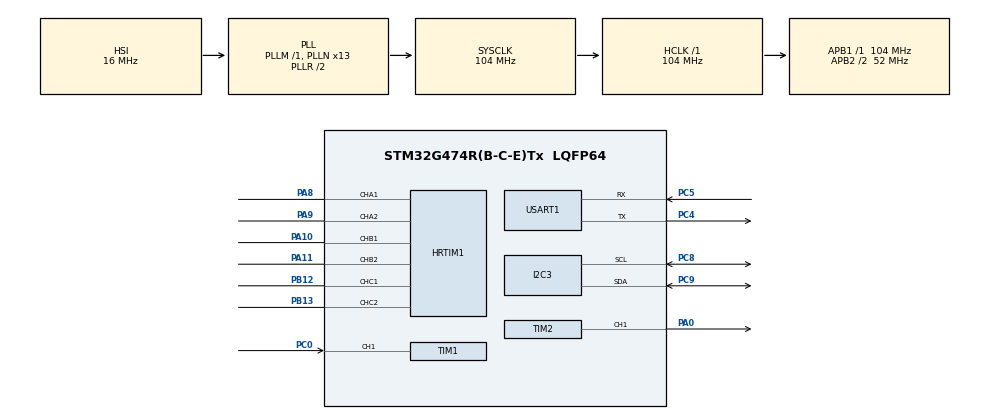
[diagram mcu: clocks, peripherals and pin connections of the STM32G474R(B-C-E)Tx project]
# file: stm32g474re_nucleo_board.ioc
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Dma.Request0=USART1_RX
Dma.Request1=USART1_TX
Dma.USART1_RX.0.Direction=DMA_PERIPH_TO_MEMORY
Dma.USART1_RX.0.EventEnable=DISABLE
Dma.USART1_RX.0.Instance=DMA1_Channel1
Dma.USART1_RX.0.MemDataAlignment=DMA_MDATAALIGN_BYTE
Dma.USART1_RX.0.MemInc=DMA_MINC_ENABLE
Dma.USART1_RX.0.Mode=DMA_NORMAL
Dma.USART1_RX.0.PeriphDataAlignment=DMA_PDATAALIGN_BYTE
Dma.USART1_RX.0.PeriphInc=DMA_PINC_DISABLE
Dma.USART1_RX.0.Polarity=HAL_DMAMUX_REQ_GEN_RISING
Dma.USART1_RX.0.Priority=DMA_PRIORITY_LOW
Dma.USART1_RX.0.RequestNumber=1
Dma.USART1_RX.0.SignalID=NONE
Dma.USART1_RX.0.SyncEnable=DISABLE
Dma.USART1_RX.0.SyncPolarity=HAL_DMAMUX_SYNC_NO_EVENT
Dma.USART1_RX.0.SyncRequestNumber=1
Dma.USART1_RX.0.SyncSignalID=NONE
Dma.USART1_TX.1.Direction=DMA_MEMORY_TO_PERIPH
Dma.USART1_TX.1.EventEnable=DISABLE
Dma.USART1_TX.1.Instance=DMA1_Channel2
Dma.USART1_TX.1.MemDataAlignment=DMA_MDATAALIGN_BYTE
Dma.USART1_TX.1.MemInc=DMA_MINC_ENABLE
Dma.USART1_TX.1.Mode=DMA_NORMAL
Dma.USART1_TX.1.PeriphDataAlignment=DMA_PDATAALIGN_BYTE
Dma.USART1_TX.1.PeriphInc=DMA_PINC_DISABLE
Dma.USART1_TX.1.Polarity=HAL_DMAMUX_REQ_GEN_RISING
Dma.USART1_TX.1.Priority=DMA_PRIORITY_MEDIUM
Dma.USART1_TX.1.RequestNumber=1
Dma.USART1_TX.1.SignalID=NONE
Dma.USART1_TX.1.SyncEnable=DISABLE
Dma.USART1_TX.1.SyncPolarity=HAL_DMAMUX_SYNC_NO_EVENT
Dma.USART1_TX.1.SyncRequestNumber=1
Dma.USART1_TX.1.SyncSignalID=NONE
FREERTOS.HEAP_NUMBER=3
FREERTOS.Tasks01=defaultTask,24,128,StartDefaultTask,Default,NULL,Dynamic,NULL,NULL
FREERTOS.configLIBRARY_MAX_SYSCALL_INTERRUPT_PRIORITY=5
FREERTOS.configTOTAL_HEAP_SIZE=0x6000
FREERTOS.configUSE_NEWLIB_REENTRANT=1
HRTIM1.CompareUnit1-Output_TA1TA2=HRTIM_COMPAREUNIT_1
HRTIM1.CompareValue1-Output_TA1TA2=0
HRTIM1.DeadTimeInsertion-Output_TB1TB2=HRTIM_TIMDEADTIMEINSERTION_ENABLED
HRTIM1.DeadTimeInsertion-Output_TC1TC2=HRTIM_TIMDEADTIMEINSERTION_ENABLED
HRTIM1.Deadtimeconfig-Output_TA1TA2=HRTIM_TIMERINDEX_TIMER_A
HRTIM1.ModeTimeBase-Output_TA1TA2=HRTIM_MODE_SINGLESHOT_RETRIGGERABLE
HRTIM1.ModeTimeBase-Output_TB1TB2=HRTIM_MODE_SINGLESHOT_RETRIGGERABLE
HRTIM1.ModeTimeBase-Output_TC1TC2=HRTIM_MODE_SINGLESHOT_RETRIGGERABLE
HRTIM1.NumberResetSource1-Output_TA1TA2=1
HRTIM1.NumberResetSource2_TA=1
HRTIM1.NumberSetSource1-Output_TA1TA2=1
HRTIM1.NumberSetSource2_TA=1
HRTIM1.ResetOnSync-Output_TA1TA2=HRTIM_SYNCRESET_ENABLED
HRTIM1.ResetOnSync-Output_TB1TB2=HRTIM_SYNCRESET_ENABLED
HRTIM1.ResetOnSync-Output_TC1TC2=HRTIM_SYNCRESET_ENABLED
HRTIM1.ResetOutput1_Source1-Output_TA1TA2=HRTIM_OUTPUTRESET_TIMCMP1
HRTIM1.ResetOutput2_Source1-Output_TA1TA2=HRTIM_OUTPUTRESET_TIMCMP1
HRTIM1.SetOutput1_Source1-Output_TA1TA2=HRTIM_OUTPUTSET_TIMCMP1
HRTIM1.SetOutput2_Source1-Output_TA1TA2=HRTIM_OUTPUTSET_TIMCMP1
HRTIM1.StartOnSync-Output_TA1TA2=HRTIM_SYNCSTART_ENABLED
HRTIM1.StartOnSync-Output_TB1TB2=HRTIM_SYNCSTART_ENABLED
HRTIM1.StartOnSync-Output_TC1TC2=HRTIM_SYNCSTART_ENABLED
HRTIM1.SyncInputSource=HRTIM_SYNCINPUTSOURCE_INTERNALEVENT
HRTIM1.SyncOptions=HRTIM_SYNCOPTION_SLAVE
I2C3.Timing=0x20C18EBF
Mcu.Family=STM32G4
Mcu.Name=STM32G474R(B-C-E)Tx
Mcu.Package=LQFP64
NVIC.DMA1_Channel1_IRQn=true\:5\:0\:false\:false\:true\:true\:false\:true\:true
NVIC.DMA1_Channel2_IRQn=true\:5\:0\:false\:false\:true\:false\:false\:true\:true
NVIC.PriorityGroup=NVIC_PRIORITYGROUP_4
NVIC.TIM1_CC_IRQn=true\:5\:0\:false\:false\:true\:true\:true\:true\:true
NVIC.TIM20_UP_IRQn=true\:15\:0\:false\:false\:true\:false\:false\:true\:true
NVIC.TimeBase=TIM20_UP_IRQn
NVIC.TimeBaseIP=TIM20
NVIC.USART1_IRQn=true\:5\:0\:true\:false\:true\:true\:true\:true\:true
PA0.Signal=S_TIM2_CH1
PA10.Mode=Output_TB1TB2
PA10.Signal=HRTIM1_CHB1
PA11.Mode=Output_TB1TB2
PA11.Signal=HRTIM1_CHB2
PA13.Mode=Trace_Asynchronous_SW
PA13.Signal=SYS_JTMS-SWDIO
PA14.Mode=Trace_Asynchronous_SW
PA14.Signal=SYS_JTCK-SWCLK
PA8.Mode=Output_TA1TA2
PA8.Signal=HRTIM1_CHA1
PA9.Mode=Output_TA1TA2
PA9.Signal=HRTIM1_CHA2
PB12.Mode=Output_TC1TC2
PB12.Signal=HRTIM1_CHC1
PB13.Mode=Output_TC1TC2
PB13.Signal=HRTIM1_CHC2
PB3.Mode=Trace_Asynchronous_SW
PB3.Signal=SYS_JTDO-SWO
PC0.Signal=S_TIM1_CH1
PC4.Mode=Asynchronous
PC4.Signal=USART1_TX
PC5.GPIO_PuPd=GPIO_PULLUP
PC5.Mode=Asynchronous
PC5.Signal=USART1_RX
PC8.GPIO_Pu=GPIO_PULLUP
PC8.Mode=I2C
PC8.Signal=I2C3_SCL
PC9.GPIO_Pu=GPIO_PULLUP
PC9.Mode=I2C
PC9.Signal=I2C3_SDA
ProjectManager.HeapSize=0x200
ProjectManager.StackSize=0x400
ProjectManager.TargetToolchain=CMake
RCC.ADC12Freq_Value=104000000
RCC.ADC345Freq_Value=104000000
RCC.AHBFreq_Value=104000000
RCC.APB1Freq_Value=104000000
RCC.APB1TimFreq_Value=104000000
RCC.APB2CLKDivider=RCC_HCLK_DIV2
RCC.APB2Freq_Value=52000000
RCC.APB2TimFreq_Value=104000000
RCC.CortexFreq_Value=104000000
RCC.EXTERNAL_CLOCK_VALUE=12288000
RCC.HCLKFreq_Value=104000000
RCC.HSE_VALUE=8000000
RCC.HSI48_VALUE=48000000
RCC.HSI_VALUE=16000000
RCC.LSE_VALUE=32768
RCC.PLLN=13
RCC.SYSCLKFreq_VALUE=104000000
RCC.SYSCLKSource=RCC_SYSCLKSOURCE_PLLCLK
RCC.USBFreq_Value=104000000
RCC.VCOOutputFreq_Value=208000000
SH.S_TIM1_CH1.0=TIM1_CH1,TriggerSource_TI1ED
SH.S_TIM2_CH1.0=TIM2_CH1,PWM Generation1 CH1
TIM1.Channel-Input_Capture1_from_TRC=TIM_CHANNEL_1
TIM1.TIM_MasterOutputTrigger=TIM_TRGO_OC1
TIM1.TIM_MasterSlaveMode=TIM_MASTERSLAVEMODE_ENABLE
TIM2.Channel-PWM\ Generation1\ CH1=TIM_CHANNEL_1
TIM2.PeriodNoDither=32768
TIM2.PulseNoDither_1=16384
USART1.FIFOMode=FIFOMODE_DISABLE
USART1.VirtualMode-Asynchronous=VM_ASYNC
VP_CRC_VS_CRC.Mode=CRC_Activate
VP_FREERTOS_VS_CMSIS_V2.Mode=CMSIS_V2
VP_HRTIM1_VS_hrtimMasterTimerNoOutput.Mode=MasterTimer
VP_HRTIM1_VirtualSync.Mode=SCOUT_SCINmodeVirtual
VP_SYS_VS_DBSignals.Mode=DisableDeadBatterySignals
VP_SYS_VS_tim20.Mode=TIM20
VP_TIM1_VS_CH1.Mode=Input_Capture1_from_TRC
VP_TIM1_VS_ClockSourceINT.Mode=Internal
VP_TIM1_VS_ControllerModeCombinedResetTrigger.Mode=Combined_Reset_Trigger_Mode
VP_TIM2_VS_ClockSourceINT.Mode=Internal
board=custom

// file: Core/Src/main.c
/* USER CODE BEGIN Header */
/**
  ******************************************************************************
  * @file           : main.c
  * @brief          : Main program body
  ******************************************************************************
  * @attention
  *
  * Copyright (c) 2025 STMicroelectronics.
  * All rights reserved.
  *
  * This software is licensed under terms that can be found in the LICENSE file
  * in the root directory of this software component.
  * If no LICENSE file comes with this software, it is provided AS-IS.
  *
  ******************************************************************************
  */
/* USER CODE END Header */
#include "main.h"
#include "cmsis_os.h"

/* USER CODE BEGIN PTD */

/* Use g_board_* naming from board.h */
#include "board.h"

/* USER CODE END PTD */

CRC_HandleTypeDef hcrc;

HRTIM_HandleTypeDef hhrtim1;

I2C_HandleTypeDef hi2c3;

TIM_HandleTypeDef htim1;
TIM_HandleTypeDef htim2;

UART_HandleTypeDef huart1;
DMA_HandleTypeDef hdma_usart1_rx;
DMA_HandleTypeDef hdma_usart1_tx;

/* Board config - g_board_* naming for controller code */
TIM_HandleTypeDef *g_board_tim_feedback = &htim1;
TIM_HandleTypeDef *g_board_tim_debug = &htim2;
HRTIM_HandleTypeDef *g_board_hrtim = &hhrtim1;
I2C_HandleTypeDef *g_board_i2c_internal = &hi2c3;
UART_HandleTypeDef *g_board_ctl_uart = &huart1;
DMA_HandleTypeDef *g_board_dma_uart_rx = &hdma_usart1_rx;
DMA_HandleTypeDef *g_board_dma_uart_tx = &hdma_usart1_tx;
CRC_HandleTypeDef *g_board_crc32 = &hcrc;

// BOARD_CONFIG instance - references to board peripherals
struct BoardConfig g_board_config = {
    .message_bus = &huart1,
    .crc32 = &hcrc
};

DAC_HandleTypeDef *g_board_dac_ch1 = (DAC_HandleTypeDef *)0;
DAC_HandleTypeDef *g_board_dac_ch2 = (DAC_HandleTypeDef *)0;
DAC_HandleTypeDef *g_board_dac_ch3 = (DAC_HandleTypeDef *)0;
DAC_HandleTypeDef *g_board_dac_ch4 = (DAC_HandleTypeDef *)0;
DAC_HandleTypeDef *g_board_dac_channels[4] = {
    (DAC_HandleTypeDef *)0,
    (DAC_HandleTypeDef *)0,
    (DAC_HandleTypeDef *)0,
    (DAC_HandleTypeDef *)0
};

/* Definitions for defaultTask */
osThreadId_t defaultTaskHandle;
const osThreadAttr_t defaultTask_attributes = {
  .name = "defaultTask",
  .priority = (osPriority_t) osPriorityNormal,
  .stack_size = 128 * 4
};
/* USER CODE BEGIN PV */
// Board definition macro (selected by CMake -DBOARD=...)
#define stm32g474re_nucleo_board
/* USER CODE END PV */

void SystemClock_Config(void);
static void MX_GPIO_Init(void);
static void MX_DMA_Init(void);
static void MX_HRTIM1_Init(void);
static void MX_TIM1_Init(void);
static void MX_TIM2_Init(void);
static void MX_I2C3_Init(void);
static void MX_CRC_Init(void);
static void MX_USART1_UART_Init(void);
void StartDefaultTask(void *argument);

int main(void)
{

  /* MCU Configuration--------------------------------------------------------*/

  /* Reset of all peripherals, Initializes the Flash interface and the Systick. */
  HAL_Init();

  /* Configure the system clock */
  SystemClock_Config();

  /* Initialize all configured peripherals */
  MX_GPIO_Init();
  MX_DMA_Init();
  MX_HRTIM1_Init();
  MX_TIM1_Init();
  MX_TIM2_Init();
  MX_I2C3_Init();
  MX_CRC_Init();
  MX_USART1_UART_Init();

  /* Init scheduler */
  osKernelInitialize();

  /* Create the thread(s) */
  /* creation of defaultTask */
  defaultTaskHandle = osThreadNew(StartDefaultTask, NULL, &defaultTask_attributes);

  /* Start scheduler */
  osKernelStart();

  /* We should never get here as control is now taken by the scheduler */

  /* Infinite loop */
  while (1)
  {

  }
}

void SystemClock_Config(void)
{
  RCC_OscInitTypeDef RCC_OscInitStruct = {0};
  RCC_ClkInitTypeDef RCC_ClkInitStruct = {0};

  /** Configure the main internal regulator output voltage
  */
  HAL_PWREx_ControlVoltageScaling(PWR_REGULATOR_VOLTAGE_SCALE1);

  /** Initializes the RCC Oscillators according to the specified parameters
  * in the RCC_OscInitTypeDef structure.
  */
  RCC_OscInitStruct.OscillatorType = RCC_OSCILLATORTYPE_HSI;
  RCC_OscInitStruct.HSIState = RCC_HSI_ON;
  RCC_OscInitStruct.HSICalibrationValue = RCC_HSICALIBRATION_DEFAULT;
  RCC_OscInitStruct.PLL.PLLState = RCC_PLL_ON;
  RCC_OscInitStruct.PLL.PLLSource = RCC_PLLSOURCE_HSI;
  RCC_OscInitStruct.PLL.PLLM = RCC_PLLM_DIV1;
  RCC_OscInitStruct.PLL.PLLN = 13;
  RCC_OscInitStruct.PLL.PLLP = RCC_PLLP_DIV2;
  RCC_OscInitStruct.PLL.PLLQ = RCC_PLLQ_DIV2;
  RCC_OscInitStruct.PLL.PLLR = RCC_PLLR_DIV2;
  if (HAL_RCC_OscConfig(&RCC_OscInitStruct) != HAL_OK)
  {
    Error_Handler();
  }

  /** Initializes the CPU, AHB and APB buses clocks
  */
  RCC_ClkInitStruct.ClockType = RCC_CLOCKTYPE_HCLK|RCC_CLOCKTYPE_SYSCLK
                              |RCC_CLOCKTYPE_PCLK1|RCC_CLOCKTYPE_PCLK2;
  RCC_ClkInitStruct.SYSCLKSource = RCC_SYSCLKSOURCE_PLLCLK;
  RCC_ClkInitStruct.AHBCLKDivider = RCC_SYSCLK_DIV1;
  RCC_ClkInitStruct.APB1CLKDivider = RCC_HCLK_DIV1;
  RCC_ClkInitStruct.APB2CLKDivider = RCC_HCLK_DIV2;

  if (HAL_RCC_ClockConfig(&RCC_ClkInitStruct, FLASH_LATENCY_3) != HAL_OK)
  {
    Error_Handler();
  }
}

static void MX_CRC_Init(void)
{

  hcrc.Instance = CRC;
  hcrc.Init.DefaultPolynomialUse = DEFAULT_POLYNOMIAL_ENABLE;
  hcrc.Init.DefaultInitValueUse = DEFAULT_INIT_VALUE_ENABLE;
  hcrc.Init.InputDataInversionMode = CRC_INPUTDATA_INVERSION_NONE;
  hcrc.Init.OutputDataInversionMode = CRC_OUTPUTDATA_INVERSION_DISABLE;
  hcrc.InputDataFormat = CRC_INPUTDATA_FORMAT_BYTES;
  if (HAL_CRC_Init(&hcrc) != HAL_OK)
  {
    Error_Handler();
  }

}

static void MX_HRTIM1_Init(void)
{

  HRTIM_TimeBaseCfgTypeDef pTimeBaseCfg = {0};
  HRTIM_TimerCfgTypeDef pTimerCfg = {0};
  HRTIM_TimerCtlTypeDef pTimerCtl = {0};
  HRTIM_CompareCfgTypeDef pCompareCfg = {0};
  HRTIM_DeadTimeCfgTypeDef pDeadTimeCfg = {0};
  HRTIM_OutputCfgTypeDef pOutputCfg = {0};

  hhrtim1.Instance = HRTIM1;
  hhrtim1.Init.HRTIMInterruptResquests = HRTIM_IT_NONE;
  hhrtim1.Init.SyncOptions = HRTIM_SYNCOPTION_SLAVE;
  hhrtim1.Init.SyncInputSource = HRTIM_SYNCINPUTSOURCE_INTERNALEVENT;
  if (HAL_HRTIM_Init(&hhrtim1) != HAL_OK)
  {
    Error_Handler();
  }
  if (HAL_HRTIM_DLLCalibrationStart(&hhrtim1, HRTIM_CALIBRATIONRATE_3) != HAL_OK)
  {
    Error_Handler();
  }
  if (HAL_HRTIM_PollForDLLCalibration(&hhrtim1, 10) != HAL_OK)
  {
    Error_Handler();
  }
  pTimeBaseCfg.Period = 0xFFDF;
  pTimeBaseCfg.RepetitionCounter = 0x00;
  pTimeBaseCfg.PrescalerRatio = HRTIM_PRESCALERRATIO_MUL32;
  pTimeBaseCfg.Mode = HRTIM_MODE_CONTINUOUS;
  if (HAL_HRTIM_TimeBaseConfig(&hhrtim1, HRTIM_TIMERINDEX_MASTER, &pTimeBaseCfg) != HAL_OK)
  {
    Error_Handler();
  }
  pTimerCfg.InterruptRequests = HRTIM_MASTER_IT_NONE;
  pTimerCfg.DMARequests = HRTIM_MASTER_DMA_NONE;
  pTimerCfg.DMASrcAddress = 0x0000;
  pTimerCfg.DMADstAddress = 0x0000;
  pTimerCfg.DMASize = 0x1;
  pTimerCfg.HalfModeEnable = HRTIM_HALFMODE_DISABLED;
  pTimerCfg.InterleavedMode = HRTIM_INTERLEAVED_MODE_DISABLED;
  pTimerCfg.StartOnSync = HRTIM_SYNCSTART_DISABLED;
  pTimerCfg.ResetOnSync = HRTIM_SYNCRESET_DISABLED;
  pTimerCfg.DACSynchro = HRTIM_DACSYNC_NONE;
  pTimerCfg.PreloadEnable = HRTIM_PRELOAD_DISABLED;
  pTimerCfg.UpdateGating = HRTIM_UPDATEGATING_INDEPENDENT;
  pTimerCfg.BurstMode = HRTIM_TIMERBURSTMODE_MAINTAINCLOCK;
  pTimerCfg.RepetitionUpdate = HRTIM_UPDATEONREPETITION_DISABLED;
  pTimerCfg.ReSyncUpdate = HRTIM_TIMERESYNC_UPDATE_UNCONDITIONAL;
  if (HAL_HRTIM_WaveformTimerConfig(&hhrtim1, HRTIM_TIMERINDEX_MASTER, &pTimerCfg) != HAL_OK)
  {
    Error_Handler();
  }
  pTimeBaseCfg.Mode = HRTIM_MODE_SINGLESHOT_RETRIGGERABLE;
  if (HAL_HRTIM_TimeBaseConfig(&hhrtim1, HRTIM_TIMERINDEX_TIMER_A, &pTimeBaseCfg) != HAL_OK)
  {
    Error_Handler();
  }
  pTimerCtl.UpDownMode = HRTIM_TIMERUPDOWNMODE_UP;
  pTimerCtl.GreaterCMP1 = HRTIM_TIMERGTCMP1_EQUAL;
  pTimerCtl.DualChannelDacEnable = HRTIM_TIMER_DCDE_DISABLED;
  if (HAL_HRTIM_WaveformTimerControl(&hhrtim1, HRTIM_TIMERINDEX_TIMER_A, &pTimerCtl) != HAL_OK)
  {
    Error_Handler();
  }
  pTimerCfg.InterruptRequests = HRTIM_TIM_IT_NONE;
  pTimerCfg.DMARequests = HRTIM_TIM_DMA_NONE;
  pTimerCfg.StartOnSync = HRTIM_SYNCSTART_ENABLED;
  pTimerCfg.ResetOnSync = HRTIM_SYNCRESET_ENABLED;
  pTimerCfg.PushPull = HRTIM_TIMPUSHPULLMODE_DISABLED;
  pTimerCfg.FaultEnable = HRTIM_TIMFAULTENABLE_NONE;
  pTimerCfg.FaultLock = HRTIM_TIMFAULTLOCK_READWRITE;
  pTimerCfg.DeadTimeInsertion = HRTIM_TIMDEADTIMEINSERTION_DISABLED;
  pTimerCfg.DelayedProtectionMode = HRTIM_TIMER_A_B_C_DELAYEDPROTECTION_DISABLED;
  pTimerCfg.UpdateTrigger = HRTIM_TIMUPDATETRIGGER_NONE;
  pTimerCfg.ResetTrigger = HRTIM_TIMRESETTRIGGER_NONE;
  pTimerCfg.ResetUpdate = HRTIM_TIMUPDATEONRESET_DISABLED;
  if (HAL_HRTIM_WaveformTimerConfig(&hhrtim1, HRTIM_TIMERINDEX_TIMER_A, &pTimerCfg) != HAL_OK)
  {
    Error_Handler();
  }
  pTimerCfg.DeadTimeInsertion = HRTIM_TIMDEADTIMEINSERTION_ENABLED;
  if (HAL_HRTIM_WaveformTimerConfig(&hhrtim1, HRTIM_TIMERINDEX_TIMER_B, &pTimerCfg) != HAL_OK)
  {
    Error_Handler();
  }
  if (HAL_HRTIM_WaveformTimerConfig(&hhrtim1, HRTIM_TIMERINDEX_TIMER_C, &pTimerCfg) != HAL_OK)
  {
    Error_Handler();
  }
  pCompareCfg.CompareValue = 0;
  if (HAL_HRTIM_WaveformCompareConfig(&hhrtim1, HRTIM_TIMERINDEX_TIMER_A, HRTIM_COMPAREUNIT_1, &pCompareCfg) != HAL_OK)
  {
    Error_Handler();
  }
  pDeadTimeCfg.Prescaler = HRTIM_TIMDEADTIME_PRESCALERRATIO_MUL8;
  pDeadTimeCfg.RisingValue = 0x000;
  pDeadTimeCfg.RisingSign = HRTIM_TIMDEADTIME_RISINGSIGN_POSITIVE;
  pDeadTimeCfg.RisingLock = HRTIM_TIMDEADTIME_RISINGLOCK_WRITE;
  pDeadTimeCfg.RisingSignLock = HRTIM_TIMDEADTIME_RISINGSIGNLOCK_WRITE;
  pDeadTimeCfg.FallingValue = 0x000;
  pDeadTimeCfg.FallingSign = HRTIM_TIMDEADTIME_FALLINGSIGN_POSITIVE;
  pDeadTimeCfg.FallingLock = HRTIM_TIMDEADTIME_FALLINGLOCK_WRITE;
  pDeadTimeCfg.FallingSignLock = HRTIM_TIMDEADTIME_FALLINGSIGNLOCK_WRITE;
  if (HAL_HRTIM_DeadTimeConfig(&hhrtim1, HRTIM_TIMERINDEX_TIMER_A, &pDeadTimeCfg) != HAL_OK)
  {
    Error_Handler();
  }
  if (HAL_HRTIM_DeadTimeConfig(&hhrtim1, HRTIM_TIMERINDEX_TIMER_B, &pDeadTimeCfg) != HAL_OK)
  {
    Error_Handler();
  }
  if (HAL_HRTIM_DeadTimeConfig(&hhrtim1, HRTIM_TIMERINDEX_TIMER_C, &pDeadTimeCfg) != HAL_OK)
  {
    Error_Handler();
  }
  pOutputCfg.Polarity = HRTIM_OUTPUTPOLARITY_HIGH;
  pOutputCfg.SetSource = HRTIM_OUTPUTSET_TIMCMP1;
  pOutputCfg.ResetSource = HRTIM_OUTPUTRESET_TIMCMP1;
  pOutputCfg.IdleMode = HRTIM_OUTPUTIDLEMODE_NONE;
  pOutputCfg.IdleLevel = HRTIM_OUTPUTIDLELEVEL_INACTIVE;
  pOutputCfg.FaultLevel = HRTIM_OUTPUTFAULTLEVEL_NONE;
  pOutputCfg.ChopperModeEnable = HRTIM_OUTPUTCHOPPERMODE_DISABLED;
  pOutputCfg.BurstModeEntryDelayed = HRTIM_OUTPUTBURSTMODEENTRY_REGULAR;
  if (HAL_HRTIM_WaveformOutputConfig(&hhrtim1, HRTIM_TIMERINDEX_TIMER_A, HRTIM_OUTPUT_TA1, &pOutputCfg) != HAL_OK)
  {
    Error_Handler();
  }
  pOutputCfg.SetSource = HRTIM_OUTPUTSET_NONE;
  pOutputCfg.ResetSource = HRTIM_OUTPUTRESET_NONE;
  if (HAL_HRTIM_WaveformOutputConfig(&hhrtim1, HRTIM_TIMERINDEX_TIMER_B, HRTIM_OUTPUT_TB1, &pOutputCfg) != HAL_OK)
  {
    Error_Handler();
  }
  if (HAL_HRTIM_WaveformOutputConfig(&hhrtim1, HRTIM_TIMERINDEX_TIMER_C, HRTIM_OUTPUT_TC1, &pOutputCfg) != HAL_OK)
  {
    Error_Handler();
  }
  pOutputCfg.SetSource = HRTIM_OUTPUTSET_TIMCMP1;
  pOutputCfg.ResetSource = HRTIM_OUTPUTRESET_TIMCMP1;
  if (HAL_HRTIM_WaveformOutputConfig(&hhrtim1, HRTIM_TIMERINDEX_TIMER_A, HRTIM_OUTPUT_TA2, &pOutputCfg) != HAL_OK)
  {
    Error_Handler();
  }
  pOutputCfg.SetSource = HRTIM_OUTPUTSET_NONE;
  pOutputCfg.ResetSource = HRTIM_OUTPUTRESET_NONE;
  if (HAL_HRTIM_WaveformOutputConfig(&hhrtim1, HRTIM_TIMERINDEX_TIMER_B, HRTIM_OUTPUT_TB2, &pOutputCfg) != HAL_OK)
  {
    Error_Handler();
  }
  if (HAL_HRTIM_WaveformOutputConfig(&hhrtim1, HRTIM_TIMERINDEX_TIMER_C, HRTIM_OUTPUT_TC2, &pOutputCfg) != HAL_OK)
  {
    Error_Handler();
  }
  if (HAL_HRTIM_TimeBaseConfig(&hhrtim1, HRTIM_TIMERINDEX_TIMER_B, &pTimeBaseCfg) != HAL_OK)
  {
    Error_Handler();
  }
  if (HAL_HRTIM_WaveformTimerControl(&hhrtim1, HRTIM_TIMERINDEX_TIMER_B, &pTimerCtl) != HAL_OK)
  {
    Error_Handler();
  }
  if (HAL_HRTIM_TimeBaseConfig(&hhrtim1, HRTIM_TIMERINDEX_TIMER_C, &pTimeBaseCfg) != HAL_OK)
  {
    Error_Handler();
  }
  if (HAL_HRTIM_WaveformTimerControl(&hhrtim1, HRTIM_TIMERINDEX_TIMER_C, &pTimerCtl) != HAL_OK)
  {
    Error_Handler();
  }
  HAL_HRTIM_MspPostInit(&hhrtim1);

}

static void MX_I2C3_Init(void)
{

  hi2c3.Instance = I2C3;
  hi2c3.Init.Timing = 0x20C18EBF;
  hi2c3.Init.OwnAddress1 = 0;
  hi2c3.Init.AddressingMode = I2C_ADDRESSINGMODE_7BIT;
  hi2c3.Init.DualAddressMode = I2C_DUALADDRESS_DISABLE;
  hi2c3.Init.OwnAddress2 = 0;
  hi2c3.Init.OwnAddress2Masks = I2C_OA2_NOMASK;
  hi2c3.Init.GeneralCallMode = I2C_GENERALCALL_DISABLE;
  hi2c3.Init.NoStretchMode = I2C_NOSTRETCH_DISABLE;
  if (HAL_I2C_Init(&hi2c3) != HAL_OK)
  {
    Error_Handler();
  }

  /** Configure Analogue filter
  */
  if (HAL_I2CEx_ConfigAnalogFilter(&hi2c3, I2C_ANALOGFILTER_ENABLE) != HAL_OK)
  {
    Error_Handler();
  }

  /** Configure Digital filter
  */
  if (HAL_I2CEx_ConfigDigitalFilter(&hi2c3, 0) != HAL_OK)
  {
    Error_Handler();
  }

}

static void MX_TIM1_Init(void)
{

  TIM_ClockConfigTypeDef sClockSourceConfig = {0};
  TIM_SlaveConfigTypeDef sSlaveConfig = {0};
  TIM_MasterConfigTypeDef sMasterConfig = {0};
  TIM_IC_InitTypeDef sConfigIC = {0};

  htim1.Instance = TIM1;
  htim1.Init.Prescaler = 0;
  htim1.Init.CounterMode = TIM_COUNTERMODE_UP;
  htim1.Init.Period = 65535;
  htim1.Init.ClockDivision = TIM_CLOCKDIVISION_DIV1;
  htim1.Init.RepetitionCounter = 0;
  htim1.Init.AutoReloadPreload = TIM_AUTORELOAD_PRELOAD_DISABLE;
  if (HAL_TIM_Base_Init(&htim1) != HAL_OK)
  {
    Error_Handler();
  }
  sClockSourceConfig.ClockSource = TIM_CLOCKSOURCE_INTERNAL;
  if (HAL_TIM_ConfigClockSource(&htim1, &sClockSourceConfig) != HAL_OK)
  {
    Error_Handler();
  }
  if (HAL_TIM_IC_Init(&htim1) != HAL_OK)
  {
    Error_Handler();
  }
  sSlaveConfig.SlaveMode = TIM_SLAVEMODE_COMBINED_RESETTRIGGER;
  sSlaveConfig.InputTrigger = TIM_TS_TI1F_ED;
  sSlaveConfig.TriggerFilter = 0;
  if (HAL_TIM_SlaveConfigSynchro(&htim1, &sSlaveConfig) != HAL_OK)
  {
    Error_Handler();
  }
  sMasterConfig.MasterOutputTrigger = TIM_TRGO_OC1;
  sMasterConfig.MasterOutputTrigger2 = TIM_TRGO2_RESET;
  sMasterConfig.MasterSlaveMode = TIM_MASTERSLAVEMODE_ENABLE;
  if (HAL_TIMEx_MasterConfigSynchronization(&htim1, &sMasterConfig) != HAL_OK)
  {
    Error_Handler();
  }
  sConfigIC.ICPolarity = TIM_INPUTCHANNELPOLARITY_RISING;
  sConfigIC.ICSelection = TIM_ICSELECTION_TRC;
  sConfigIC.ICPrescaler = TIM_ICPSC_DIV1;
  sConfigIC.ICFilter = 0;
  if (HAL_TIM_IC_ConfigChannel(&htim1, &sConfigIC, TIM_CHANNEL_1) != HAL_OK)
  {
    Error_Handler();
  }

}

static void MX_TIM2_Init(void)
{

  TIM_ClockConfigTypeDef sClockSourceConfig = {0};
  TIM_MasterConfigTypeDef sMasterConfig = {0};
  TIM_OC_InitTypeDef sConfigOC = {0};

  htim2.Instance = TIM2;
  htim2.Init.Prescaler = 0;
  htim2.Init.CounterMode = TIM_COUNTERMODE_UP;
  htim2.Init.Period = 32768;
  htim2.Init.ClockDivision = TIM_CLOCKDIVISION_DIV1;
  htim2.Init.AutoReloadPreload = TIM_AUTORELOAD_PRELOAD_DISABLE;
  if (HAL_TIM_Base_Init(&htim2) != HAL_OK)
  {
    Error_Handler();
  }
  sClockSourceConfig.ClockSource = TIM_CLOCKSOURCE_INTERNAL;
  if (HAL_TIM_ConfigClockSource(&htim2, &sClockSourceConfig) != HAL_OK)
  {
    Error_Handler();
  }
  if (HAL_TIM_PWM_Init(&htim2) != HAL_OK)
  {
    Error_Handler();
  }
  sMasterConfig.MasterOutputTrigger = TIM_TRGO_RESET;
  sMasterConfig.MasterSlaveMode = TIM_MASTERSLAVEMODE_DISABLE;
  if (HAL_TIMEx_MasterConfigSynchronization(&htim2, &sMasterConfig) != HAL_OK)
  {
    Error_Handler();
  }
  sConfigOC.OCMode = TIM_OCMODE_PWM1;
  sConfigOC.Pulse = 16384;
  sConfigOC.OCPolarity = TIM_OCPOLARITY_HIGH;
  sConfigOC.OCFastMode = TIM_OCFAST_DISABLE;
  if (HAL_TIM_PWM_ConfigChannel(&htim2, &sConfigOC, TIM_CHANNEL_1) != HAL_OK)
  {
    Error_Handler();
  }
  HAL_TIM_MspPostInit(&htim2);

}

static void MX_USART1_UART_Init(void)
{

  huart1.Instance = USART1;
  huart1.Init.BaudRate = 115200;
  huart1.Init.WordLength = UART_WORDLENGTH_8B;
  huart1.Init.StopBits = UART_STOPBITS_1;
  huart1.Init.Parity = UART_PARITY_NONE;
  huart1.Init.Mode = UART_MODE_TX_RX;
  huart1.Init.HwFlowCtl = UART_HWCONTROL_NONE;
  huart1.Init.OverSampling = UART_OVERSAMPLING_16;
  huart1.Init.OneBitSampling = UART_ONE_BIT_SAMPLE_DISABLE;
  huart1.Init.ClockPrescaler = UART_PRESCALER_DIV1;
  huart1.AdvancedInit.AdvFeatureInit = UART_ADVFEATURE_NO_INIT;
  if (HAL_UART_Init(&huart1) != HAL_OK)
  {
    Error_Handler();
  }
  if (HAL_UARTEx_SetTxFifoThreshold(&huart1, UART_TXFIFO_THRESHOLD_1_8) != HAL_OK)
  {
    Error_Handler();
  }
  if (HAL_UARTEx_SetRxFifoThreshold(&huart1, UART_RXFIFO_THRESHOLD_1_8) != HAL_OK)
  {
    Error_Handler();
  }
  if (HAL_UARTEx_DisableFifoMode(&huart1) != HAL_OK)
  {
    Error_Handler();
  }

}

static void MX_DMA_Init(void)
{

  /* DMA controller clock enable */
  __HAL_RCC_DMAMUX1_CLK_ENABLE();
  __HAL_RCC_DMA1_CLK_ENABLE();

  /* DMA interrupt init */
  /* DMA1_Channel1_IRQn interrupt configuration */
  HAL_NVIC_SetPriority(DMA1_Channel1_IRQn, 5, 0);
  HAL_NVIC_EnableIRQ(DMA1_Channel1_IRQn);
  /* DMA1_Channel2_IRQn interrupt configuration */
  HAL_NVIC_SetPriority(DMA1_Channel2_IRQn, 5, 0);
  HAL_NVIC_EnableIRQ(DMA1_Channel2_IRQn);

}

static void MX_GPIO_Init(void)
{

  /* GPIO Ports Clock Enable */
  __HAL_RCC_GPIOC_CLK_ENABLE();
  __HAL_RCC_GPIOA_CLK_ENABLE();
  __HAL_RCC_GPIOB_CLK_ENABLE();

}

void StartDefaultTask(void *argument)
{
  /* USER CODE BEGIN 5 */
  /* Infinite loop */
  controller_system_init();
  for(;;)
  {
    osDelay(1);
  }
  /* USER CODE END 5 */
}

void HAL_TIM_PeriodElapsedCallback(TIM_HandleTypeDef *htim)
{
  if (htim->Instance == TIM20)
  {
    HAL_IncTick();
  }
}

void Error_Handler(void)
{
  __disable_irq();
  while (1)
  {
  }
}
